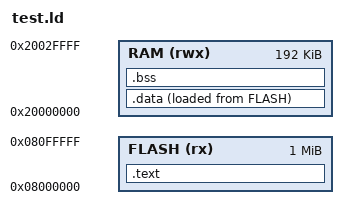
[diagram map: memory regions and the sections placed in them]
MEMORY { FLASH (rx) : ORIGIN = 0x08000000, LENGTH = 1024K
         RAM (rwx) : ORIGIN = 0x20000000, LENGTH = 192K }
SECTIONS {
 .text : { *(.text*) *(.rodata*) } > FLASH
 .data : { *(.data*) } > RAM AT> FLASH
 .bss (NOLOAD) : { *(.bss*) *(COMMON) } > RAM
}
